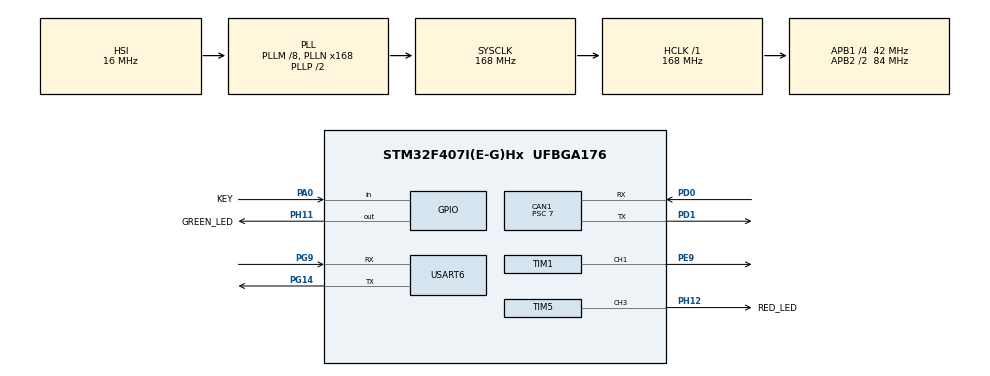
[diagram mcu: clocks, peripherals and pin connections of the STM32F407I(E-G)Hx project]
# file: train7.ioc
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CAN1.BS1=CAN_BS1_4TQ
CAN1.CalculateBaudRate=999999
CAN1.CalculateTimeBit=1000
CAN1.CalculateTimeQuantum=166.66666666666669
CAN1.Prescaler=7
Dma.Request0=USART6_RX
Dma.Request1=USART6_TX
Dma.USART6_RX.0.Direction=DMA_PERIPH_TO_MEMORY
Dma.USART6_RX.0.FIFOMode=DMA_FIFOMODE_DISABLE
Dma.USART6_RX.0.Instance=DMA2_Stream1
Dma.USART6_RX.0.MemDataAlignment=DMA_MDATAALIGN_BYTE
Dma.USART6_RX.0.MemInc=DMA_MINC_ENABLE
Dma.USART6_RX.0.Mode=DMA_NORMAL
Dma.USART6_RX.0.PeriphDataAlignment=DMA_PDATAALIGN_BYTE
Dma.USART6_RX.0.PeriphInc=DMA_PINC_DISABLE
Dma.USART6_RX.0.Priority=DMA_PRIORITY_LOW
Dma.USART6_TX.1.Direction=DMA_MEMORY_TO_PERIPH
Dma.USART6_TX.1.FIFOMode=DMA_FIFOMODE_DISABLE
Dma.USART6_TX.1.Instance=DMA2_Stream6
Dma.USART6_TX.1.MemDataAlignment=DMA_MDATAALIGN_BYTE
Dma.USART6_TX.1.MemInc=DMA_MINC_ENABLE
Dma.USART6_TX.1.Mode=DMA_NORMAL
Dma.USART6_TX.1.PeriphDataAlignment=DMA_PDATAALIGN_BYTE
Dma.USART6_TX.1.PeriphInc=DMA_PINC_DISABLE
Dma.USART6_TX.1.Priority=DMA_PRIORITY_LOW
FREERTOS.Queues01=KEY_SERVO,16,uint32_t,0,Dynamic,NULL,NULL
FREERTOS.Tasks01=LED_TASK,8,128,START_LED_TASK,Default,NULL,Dynamic,NULL,NULL;KEY_TASK,8,128,START_KEY_TASK,Default,NULL,Dynamic,NULL,NULL;SERVO_TASK,24,128,START_SERVO_TASK,Default,NULL,Dynamic,NULL,NULL;PRINT_SPEED_TAS,24,256,START_PRINT_SPEED_TASK,Default,NULL,Dynamic,NULL,NULL;UART_TASK,32,128,START_UART_TASK,Default,NULL,Dynamic,NULL,NULL
FREERTOS.configUSE_NEWLIB_REENTRANT=1
Mcu.Family=STM32F4
Mcu.Name=STM32F407I(E-G)Hx
Mcu.Package=UFBGA176
NVIC.CAN1_RX0_IRQn=true\:5\:0\:false\:false\:true\:true\:true\:true\:true
NVIC.DMA2_Stream1_IRQn=true\:5\:0\:false\:false\:true\:true\:false\:true\:true
NVIC.DMA2_Stream6_IRQn=true\:5\:0\:false\:false\:true\:true\:false\:true\:true
NVIC.PriorityGroup=NVIC_PRIORITYGROUP_4
NVIC.TIM4_IRQn=true\:15\:0\:false\:false\:true\:false\:false\:true\:true
NVIC.TimeBase=TIM4_IRQn
NVIC.TimeBaseIP=TIM4
NVIC.USART6_IRQn=true\:5\:0\:false\:false\:true\:true\:true\:true\:true
PA0-WKUP.GPIO_Label=KEY
PA0-WKUP.GPIO_PuPd=GPIO_PULLUP
PA0-WKUP.Signal=GPIO_Input
PA13.Mode=Serial_Wire
PA13.Signal=SYS_JTMS-SWDIO
PA14.Mode=Serial_Wire
PA14.Signal=SYS_JTCK-SWCLK
PD0.Mode=CAN_Activate
PD0.Signal=CAN1_RX
PD1.Mode=CAN_Activate
PD1.Signal=CAN1_TX
PE9.Signal=S_TIM1_CH1
PG14.Mode=Asynchronous
PG14.Signal=USART6_TX
PG9.Mode=Asynchronous
PG9.Signal=USART6_RX
PH0-OSC_IN.Mode=HSE-External-Oscillator
PH0-OSC_IN.Signal=RCC_OSC_IN
PH1-OSC_OUT.Mode=HSE-External-Oscillator
PH1-OSC_OUT.Signal=RCC_OSC_OUT
PH11.GPIO_Label=GREEN_LED
PH11.Signal=GPIO_Output
PH12.GPIO_Label=RED_LED
PH12.Signal=S_TIM5_CH3
ProjectManager.HeapSize=0x200
ProjectManager.StackSize=0x400
ProjectManager.TargetToolchain=STM32CubeIDE
RCC.48MHZClocksFreq_Value=84000000
RCC.AHBFreq_Value=168000000
RCC.APB1CLKDivider=RCC_HCLK_DIV4
RCC.APB1Freq_Value=42000000
RCC.APB1TimFreq_Value=84000000
RCC.APB2CLKDivider=RCC_HCLK_DIV2
RCC.APB2Freq_Value=84000000
RCC.APB2TimFreq_Value=168000000
RCC.CortexFreq_Value=168000000
RCC.HCLKFreq_Value=168000000
RCC.HSE_VALUE=25000000
RCC.HSI_VALUE=16000000
RCC.LSE_VALUE=32768
RCC.PLLM=8
RCC.PLLN=168
RCC.SYSCLKFreq_VALUE=168000000
RCC.SYSCLKSource=RCC_SYSCLKSOURCE_PLLCLK
RCC.VCOOutputFreq_Value=336000000
SH.S_TIM1_CH1.0=TIM1_CH1,PWM Generation1 CH1
SH.S_TIM5_CH3.0=TIM5_CH3,PWM Generation3 CH3
TIM1.Channel-PWM\ Generation1\ CH1=TIM_CHANNEL_1
TIM1.Period=20000-1
TIM1.Prescaler=168-1
TIM5.Channel-PWM\ Generation3\ CH3=TIM_CHANNEL_3
TIM5.Period=1000-1
TIM5.Prescaler=168-1
USART6.VirtualMode=VM_ASYNC
VP_FREERTOS_VS_CMSIS_V2.Mode=CMSIS_V2
VP_SYS_VS_tim4.Mode=TIM4
VP_TIM1_VS_ClockSourceINT.Mode=Internal
board=custom

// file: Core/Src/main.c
/* USER CODE BEGIN Header */
/**
  ******************************************************************************
  * @file           : main.c
  * @brief          : Main program body
  ******************************************************************************
  * @attention
  *
  * Copyright (c) 2026 STMicroelectronics.
  * All rights reserved.
  *
  * This software is licensed under terms that can be found in the LICENSE file
  * in the root directory of this software component.
  * If no LICENSE file comes with this software, it is provided AS-IS.
  *
  ******************************************************************************
  */
/* USER CODE END Header */
#include "main.h"
#include "cmsis_os.h"
#include "can.h"
#include "dma.h"
#include "tim.h"
#include "usart.h"
#include "gpio.h"

/* USER CODE BEGIN Includes */
#include "PID.h"
#include "bsp_can.h"
/* USER CODE END Includes */

void SystemClock_Config(void);
void MX_FREERTOS_Init(void);

int main(void)
{

  /* MCU Configuration--------------------------------------------------------*/

  /* Reset of all peripherals, Initializes the Flash interface and the Systick. */
  HAL_Init();

  /* Configure the system clock */
  SystemClock_Config();

  /* Initialize all configured peripherals */
  MX_GPIO_Init();
  MX_DMA_Init();
  MX_CAN1_Init();
  MX_TIM1_Init();
  MX_USART6_UART_Init();
  MX_TIM5_Init();
  /* USER CODE BEGIN 2 */
  /* TIM5 计数器启动（红灯 PWM 用；下面还会单独启动 CH3 输出） */
  HAL_TIM_Base_Start(&htim5);
  /* 舵机 PWM 通道启动：TIM1_CH1 → PE9（C 板 PWM 接口 C1） */
  HAL_TIM_PWM_Start(&htim1,TIM_CHANNEL_1);
  /* 红灯 PWM 通道启动：TIM5_CH3 → PH12，只有启动后改占空比才有效 */
  HAL_TIM_PWM_Start(&htim5, TIM_CHANNEL_3);
  /* 速度环 PID 参数：kp=14, ki=1, kd=0（实测扫参得到的最优附近） */
  PID_Init(&speed_pid,14,1,0);
  /* CAN1 过滤器 + 启动 + 接收中断，电机反馈从这里进来 */
  can_filter_init();
  /* USER CODE END 2 */

  /* Init scheduler */
  osKernelInitialize();  /* Call init function for freertos objects (in cmsis_os2.c) */
  MX_FREERTOS_Init();

  /* Start scheduler */
  osKernelStart();

  /* We should never get here as control is now taken by the scheduler */

  /* Infinite loop */
  while (1)
  {

  }
}

void SystemClock_Config(void)
{
  RCC_OscInitTypeDef RCC_OscInitStruct = {0};
  RCC_ClkInitTypeDef RCC_ClkInitStruct = {0};

  /** Configure the main internal regulator output voltage
  */
  __HAL_RCC_PWR_CLK_ENABLE();
  __HAL_PWR_VOLTAGESCALING_CONFIG(PWR_REGULATOR_VOLTAGE_SCALE1);

  /** Initializes the RCC Oscillators according to the specified parameters
  * in the RCC_OscInitTypeDef structure.
  */
  RCC_OscInitStruct.OscillatorType = RCC_OSCILLATORTYPE_HSI;
  RCC_OscInitStruct.HSIState = RCC_HSI_ON;
  RCC_OscInitStruct.HSICalibrationValue = RCC_HSICALIBRATION_DEFAULT;
  RCC_OscInitStruct.PLL.PLLState = RCC_PLL_ON;
  RCC_OscInitStruct.PLL.PLLSource = RCC_PLLSOURCE_HSI;
  RCC_OscInitStruct.PLL.PLLM = 8;
  RCC_OscInitStruct.PLL.PLLN = 168;
  RCC_OscInitStruct.PLL.PLLP = RCC_PLLP_DIV2;
  RCC_OscInitStruct.PLL.PLLQ = 4;
  if (HAL_RCC_OscConfig(&RCC_OscInitStruct) != HAL_OK)
  {
    Error_Handler();
  }

  /** Initializes the CPU, AHB and APB buses clocks
  */
  RCC_ClkInitStruct.ClockType = RCC_CLOCKTYPE_HCLK|RCC_CLOCKTYPE_SYSCLK
                              |RCC_CLOCKTYPE_PCLK1|RCC_CLOCKTYPE_PCLK2;
  RCC_ClkInitStruct.SYSCLKSource = RCC_SYSCLKSOURCE_PLLCLK;
  RCC_ClkInitStruct.AHBCLKDivider = RCC_SYSCLK_DIV1;
  RCC_ClkInitStruct.APB1CLKDivider = RCC_HCLK_DIV4;
  RCC_ClkInitStruct.APB2CLKDivider = RCC_HCLK_DIV2;

  if (HAL_RCC_ClockConfig(&RCC_ClkInitStruct, FLASH_LATENCY_5) != HAL_OK)
  {
    Error_Handler();
  }
}

void HAL_TIM_PeriodElapsedCallback(TIM_HandleTypeDef *htim)
{
  if (htim->Instance == TIM4)
  {
    HAL_IncTick();
  }
}

void Error_Handler(void)
{
  __disable_irq();
  while (1)
  {
  }
}

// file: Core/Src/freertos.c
/* USER CODE BEGIN Header */
/**
  ******************************************************************************
  * File Name          : freertos.c
  * Description        : Code for freertos applications
  ******************************************************************************
  * @attention
  *
  * Copyright (c) 2026 STMicroelectronics.
  * All rights reserved.
  *
  * This software is licensed under terms that can be found in the LICENSE file
  * in the root directory of this software component.
  * If no LICENSE file comes with this software, it is provided AS-IS.
  *
  ******************************************************************************
  */
/* USER CODE END Header */

#include "FreeRTOS.h"
#include "task.h"
#include "main.h"
#include "cmsis_os.h"

/* USER CODE BEGIN Includes */
#include "app_tasks.h"
/* USER CODE END Includes */

/* Definitions for LED_TASK */
osThreadId_t LED_TASKHandle;
const osThreadAttr_t LED_TASK_attributes = {
  .name = "LED_TASK",
  .stack_size = 128 * 4,
  .priority = (osPriority_t) osPriorityLow,
};
/* Definitions for KEY_TASK */
osThreadId_t KEY_TASKHandle;
const osThreadAttr_t KEY_TASK_attributes = {
  .name = "KEY_TASK",
  .stack_size = 128 * 4,
  .priority = (osPriority_t) osPriorityLow,
};
/* Definitions for SERVO_TASK */
osThreadId_t SERVO_TASKHandle;
const osThreadAttr_t SERVO_TASK_attributes = {
  .name = "SERVO_TASK",
  .stack_size = 128 * 4,
  .priority = (osPriority_t) osPriorityNormal,
};
/* Definitions for PRINT_SPEED_TAS */
osThreadId_t PRINT_SPEED_TASHandle;
const osThreadAttr_t PRINT_SPEED_TAS_attributes = {
  .name = "PRINT_SPEED_TAS",
  .stack_size = 256 * 4,
  .priority = (osPriority_t) osPriorityNormal,
};
/* Definitions for UART_TASK */
osThreadId_t UART_TASKHandle;
const osThreadAttr_t UART_TASK_attributes = {
  .name = "UART_TASK",
  .stack_size = 128 * 4,
  .priority = (osPriority_t) osPriorityAboveNormal,
};
/* Definitions for KEY_SERVO */
osMessageQueueId_t KEY_SERVOHandle;
const osMessageQueueAttr_t KEY_SERVO_attributes = {
  .name = "KEY_SERVO"
};

void START_LED_TASK(void *argument);
void START_KEY_TASK(void *argument);
void START_SERVO_TASK(void *argument);
void START_PRINT_SPEED_TASK(void *argument);
void START_UART_TASK(void *argument);

void MX_FREERTOS_Init(void); /* (MISRA C 2004 rule 8.1) */

void MX_FREERTOS_Init(void) {

  /* Create the queue(s) */
  /* creation of KEY_SERVO */
  KEY_SERVOHandle = osMessageQueueNew (16, sizeof(uint32_t), &KEY_SERVO_attributes);

  /* Create the thread(s) */
  /* creation of LED_TASK */
  LED_TASKHandle = osThreadNew(START_LED_TASK, NULL, &LED_TASK_attributes);

  /* creation of KEY_TASK */
  KEY_TASKHandle = osThreadNew(START_KEY_TASK, NULL, &KEY_TASK_attributes);

  /* creation of SERVO_TASK */
  SERVO_TASKHandle = osThreadNew(START_SERVO_TASK, NULL, &SERVO_TASK_attributes);

  /* creation of PRINT_SPEED_TAS */
  PRINT_SPEED_TASHandle = osThreadNew(START_PRINT_SPEED_TASK, NULL, &PRINT_SPEED_TAS_attributes);

  /* creation of UART_TASK */
  UART_TASKHandle = osThreadNew(START_UART_TASK, NULL, &UART_TASK_attributes);

}

void START_LED_TASK(void *argument)
{
  /* USER CODE BEGIN START_LED_TASK */
  APP_LED_TASK(argument);
  /* USER CODE END START_LED_TASK */
}

void START_KEY_TASK(void *argument)
{
  /* USER CODE BEGIN START_KEY_TASK */
  APP_KEY_TASK(argument);
  /* USER CODE END START_KEY_TASK */
}

void START_SERVO_TASK(void *argument)
{
  /* USER CODE BEGIN START_SERVO_TASK */
  APP_SERVO_TASK(argument);
  /* USER CODE END START_SERVO_TASK */
}

void START_PRINT_SPEED_TASK(void *argument)
{
  /* USER CODE BEGIN START_PRINT_SPEED_TASK */
  APP_PRINT_SPEED_TASK(argument);
  /* USER CODE END START_PRINT_SPEED_TASK */
}

void START_UART_TASK(void *argument) {
  /* USER CODE BEGIN START_UART_TASK */
  APP_UART_TASK(argument);
  /* USER CODE END START_UART_TASK */
}
